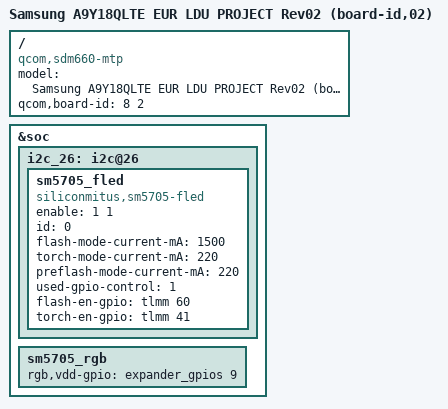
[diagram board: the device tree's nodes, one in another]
/*
 * Copyright (c) 2017, The Linux Foundation. All rights reserved.
 *
 * This program is free software; you can redistribute it and/or modify
 * it under the terms of the GNU General Public License version 2 and
 * only version 2 as published by the Free Software Foundation.
 *
 * This program is distributed in the hope that it will be useful,
 * but WITHOUT ANY WARRANTY; without even the implied warranty of
 * MERCHANTABILITY or FITNESS FOR A PARTICULAR PURPOSE.  See the
 * GNU General Public License for more details.
 */


/dts-v1/;

#include "../qcom/sdm660.dtsi"
#include "../qcom/sdm660-mtp.dtsi"
#include "../qcom/msm-pm660a.dtsi"

#include "sdm660-sec-common.dtsi"
#include "sdm660-sec-a9y18qlte-audio.dtsi"
#include "sdm660-sec-a9y18qlte-eurldu-r02.dtsi"
#include "sdm660-sec-a9y18qlte-eur-pinctrl-r02.dtsi"
#include "sdm660-sec-a9y18qlte-display-r01.dtsi"
#include "sdm660-sec-a9y18qlte-battery-common.dtsi"
#include "sdm660-sec-a9y18qlte-muic-common.dtsi"
#include "sdm660-sec-a9y18qlte-eur-fingerprint-sensor_01.dtsi"
#include "sdm660-camera-sensor-a9y18qlte_eur-r01.dtsi"
#include "sdm660-sec-a9y18qlte-nfc-eur-r00.dtsi"
#include "../../../../drivers/leds/tuning/a9y18qlte_led_tuning-r00.dtsi"

/ {
	model = "Samsung A9Y18QLTE EUR LDU PROJECT Rev02 (board-id,02)";
	compatible = "qcom,sdm660-mtp", "qcom,sdm660", "qcom,mtp";
	qcom,board-id = <8 2>;
};

&soc {
	i2c_26: i2c@26 {
		sm5705_fled {
			compatible = "siliconmitus,sm5705-fled";
			enable = <1 1>;
			id= <0>;
			status = "okay";
			flash-mode-current-mA = <1500>;
			torch-mode-current-mA = <220>;
			preflash-mode-current-mA = <220>;
			used-gpio-control = <1>;
			flash-en-gpio = <&tlmm 60 0x00>;
			torch-en-gpio = <&tlmm 41 0x00>;
		};
	};

	sm5705_rgb {
		rgb,vdd-gpio = <&expander_gpios 9 0x0>;
	};
};
